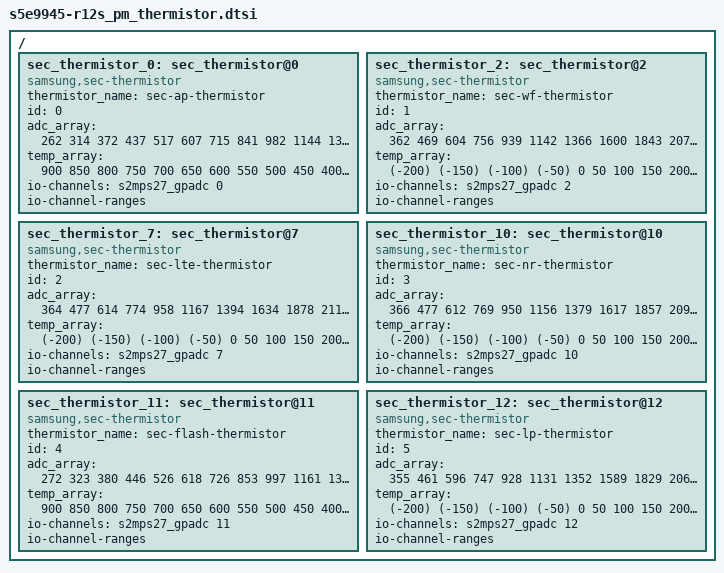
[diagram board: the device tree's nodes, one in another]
/*
 * SAMSUNG S5E9945 Power Management device tree source
 *
 * Copyright (c) 2024 Samsung Electronics Co., Ltd.
 *		http://www.samsung.com
 *
 * This program is free software; you can redistribute it and/or modify
 * it under the terms of the GNU General Public License version 2 as
 * published by the Free Software Foundation.
 */

/ {
	fragment@model {
		target-path = "/";
		__overlay__ {
			sec_thermistor_0: sec_thermistor@0 {
				compatible = "samsung,sec-thermistor";
				status = "okay";
				thermistor_name = "sec-ap-thermistor";
				id = <0>;

				adc_array = <262 314 372 437 517 607 715 841 982 1144
					1327 1524 1740 1968 2202 2445 2681 2908 3114 3294
					3455 3591 3701>;

				temp_array = <900 850 800 750 700 650 600 550 500 450
					  400 350 300 250 200 150 100 50 0 (-50)
					  (-100) (-150) (-200)>;

				io-channels = <&s2mps27_gpadc 0>;
				io-channel-names = "adc-ap-temp";
				io-channel-ranges;
			};

			sec_thermistor_2: sec_thermistor@2 {
				compatible = "samsung,sec-thermistor";
				status = "okay";
				thermistor_name = "sec-wf-thermistor";
				id = <1>;

				adc_array = <362 469 604 756 939 1142 1366 1600 1843 2078
					2310 2525 2730 2916 3084 3228 3356 3465 3557 3640
					3707 3765 3816>;

				temp_array = <(-200) (-150) (-100) (-50) 0 50 100 150 200 250
					300 350 400 450 500 550 600 650 700 750
					800 850 900>;

				io-channels = <&s2mps27_gpadc 2>;
				io-channel-names = "adc-wf-temp";
				io-channel-ranges;
			};

			sec_thermistor_7: sec_thermistor@7 {
				compatible = "samsung,sec-thermistor";
				status = "okay";
				thermistor_name = "sec-lte-thermistor";
				id = <2>;

				adc_array = <364 477 614 774 958 1167 1394 1634 1878 2119
					2351 2570 2771 2953 3117 3257 3383 3489 3580 3658
					3723 3780 3831>;

				temp_array = <(-200) (-150) (-100) (-50) 0 50 100 150 200 250
					300 350 400 450 500 550 600 650 700 750
					800 850 900>;

				io-channels = <&s2mps27_gpadc 7>;
				io-channel-names = "adc-lte-temp";
				io-channel-ranges;
			};

			sec_thermistor_10: sec_thermistor@10 {
				compatible = "samsung,sec-thermistor";
				status = "okay";
				thermistor_name = "sec-nr-thermistor";
				id = <3>;

				adc_array = <366 477 612 769 950 1156 1379 1617 1857 2093
					2325 2540 2745 2930 3096 3237 3367 3475 3566 3647
					3714 3772 3823>;

				temp_array = <(-200) (-150) (-100) (-50) 0 50 100 150 200 250
					300 350 400 450 500 550 600 650 700 750
					800 850 900>;

				io-channels = <&s2mps27_gpadc 10>;
				io-channel-names = "adc-nr-temp";
				io-channel-ranges;
			};

			sec_thermistor_11: sec_thermistor@11 {
				compatible = "samsung,sec-thermistor";
				status = "okay";
				thermistor_name = "sec-flash-thermistor";
				id = <4>;

				adc_array = <272 323 380 446 526 618 726 853 997 1161
					1347 1551 1770 2003 2244 2486 2726 2952 3159 3342
					3498 3631 3741>;

				temp_array = <900 850 800 750 700 650 600 550 500 450
					  400 350 300 250 200 150 100 50 0 (-50)
					  (-100) (-150) (-200)>;

				io-channels = <&s2mps27_gpadc 11>;
				io-channel-names = "adc-flash-temp";
				io-channel-ranges;
			};

			sec_thermistor_12: sec_thermistor@12 {
				compatible = "samsung,sec-thermistor";
				status = "okay";
				thermistor_name = "sec-lp-thermistor";
				id = <5>;

				adc_array = <355 461 596 747 928 1131 1352 1589 1829 2065
					2295 2515 2723 2910 3078 3221 3351 3460 3553 3635
					3703 3762 3811>;

				temp_array = <(-200) (-150) (-100) (-50) 0 50 100 150 200 250
					300 350 400 450 500 550 600 650 700 750
					800 850 900>;

				io-channels = <&s2mps27_gpadc 12>;
				io-channel-names = "adc-lp-temp";
				io-channel-ranges;
			};
		}; /* end of __overlay__ */
	}; /* end of fragment */
}; /* end of root */
